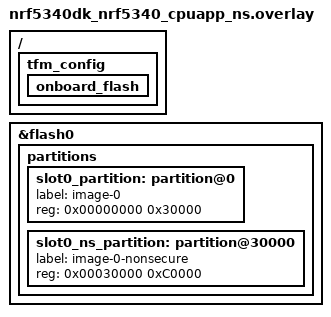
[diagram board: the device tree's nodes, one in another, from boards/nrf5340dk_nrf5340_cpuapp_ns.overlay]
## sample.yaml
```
sample:
  description: TF-M with no bootloader
  name: tfm-no-bl2
tests:
  sample.tfm.tfm_no_bl2:
    tags: trusted-firmware-m
    build_only: true
    platform_allow:
      - nrf5340dk/nrf5340/cpuapp/ns
    integration_platforms:
      - nrf5340dk/nrf5340/cpuapp/ns
```

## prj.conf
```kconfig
# TF-M build without BL2
CONFIG_TFM_DEVICETREE_LAYOUT=y
CONFIG_TFM_BL2=n
```

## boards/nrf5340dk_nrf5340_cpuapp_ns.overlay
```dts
/*
 * Copyright (c) 2024 Embeint Inc
 *
 * SPDX-License-Identifier: Apache-2.0
 */

/delete-node/ &boot_partition;
/delete-node/ &slot0_partition;
/delete-node/ &slot0_ns_partition;
/delete-node/ &slot1_partition;
/delete-node/ &slot1_ns_partition;

/ {
    tfm_config {
        onboard_flash {
            /delete-property/ img-bl2;
            /delete-property/ img-secondary-secure;
            /delete-property/ img-secondary-nonsecure;
        };
    };
};

&flash0 {
    partitions {
        slot0_partition: partition@0 {
            label = "image-0";
            reg = <0x00000000 0x30000>;
        };
        slot0_ns_partition: partition@30000 {
            label = "image-0-nonsecure";
            reg = <0x00030000 0xC0000>;
        };
    };
};
```

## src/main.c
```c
/**
 * @file
 * @copyright 2024 Embeint Inc
 * @author Jordan Yates <jordan@embeint.com>
 *
 * SPDX-License-Identifier: Apache-2.0
 */

#include <zephyr/kernel.h>

int main(void)
{
	printk("Booted TF-M with no BL2\n");

	for (;;) {
		printk("Uptime %6d\n", k_uptime_seconds());
		k_sleep(K_SECONDS(1));
	}
	return 0;
}
```
